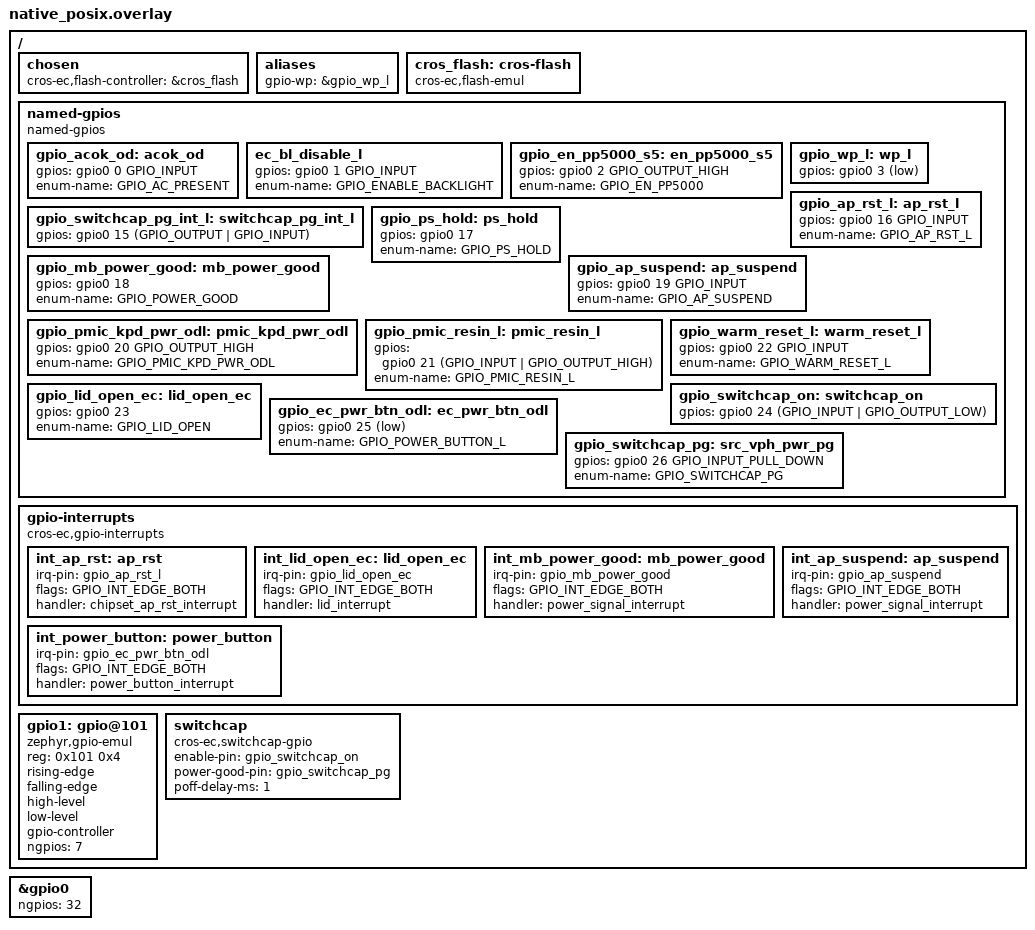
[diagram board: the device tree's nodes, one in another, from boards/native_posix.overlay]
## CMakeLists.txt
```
# Copyright 2021 The ChromiumOS Authors
# Use of this source code is governed by a BSD-style license that can be
# found in the LICENSE file.

cmake_minimum_required(VERSION 3.13.1)
find_package(Zephyr REQUIRED HINTS "${ZEPHYR_BASE}")
project(qcom_power)

# Include the local test directory for shimmed_test_tasks.h
zephyr_include_directories("${CMAKE_CURRENT_SOURCE_DIR}")

FILE(GLOB_RECURSE test_sources src/*.c)
target_sources(app PRIVATE ${test_sources})
```

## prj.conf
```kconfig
# Copyright 2022 The ChromiumOS Authors
# Use of this source code is governed by a BSD-style license that can be
# found in the LICENSE file.

CONFIG_ASSERT=y
CONFIG_PLATFORM_EC_DEBUG_ASSERT=n
CONFIG_TEST=y
CONFIG_ZTEST=y
CONFIG_ZTEST_ASSERT_VERBOSE=1
CONFIG_ZTEST_MOCKING=y

CONFIG_INPUT=y

# Print logs from Zephyr LOG_MODULE to stdout
CONFIG_UART_NATIVE_PTY_0_ON_STDINOUT=y

CONFIG_CROS_EC=y
CONFIG_EMUL=y
CONFIG_FLASH=y
CONFIG_GPIO=y
CONFIG_GPIO_GET_CONFIG=y
CONFIG_PLATFORM_EC=y
CONFIG_RING_BUFFER=y
CONFIG_SERIAL=y
CONFIG_SHELL_BACKEND_DUMMY=y
CONFIG_SHELL_BACKEND_DUMMY_BUF_SIZE=2000
CONFIG_SHELL_BACKEND_SERIAL=n
CONFIG_SHIMMED_TASKS=y

# QCom power sequencing
CONFIG_AP_ARM_QUALCOMM_SC7280=y
CONFIG_PLATFORM_EC_CHIPSET_RESUME_INIT_HOOK=y
CONFIG_PLATFORM_EC_EXTPOWER=y
CONFIG_PLATFORM_EC_EXTPOWER_GPIO=y
CONFIG_PLATFORM_EC_HOSTCMD=y
CONFIG_PLATFORM_EC_LID_SWITCH=y
CONFIG_PLATFORM_EC_POWERSEQ=y
CONFIG_PLATFORM_EC_POWERSEQ_HOST_SLEEP=y
CONFIG_PLATFORM_EC_POWERSEQ_SC7280=y
CONFIG_PLATFORM_EC_POWER_BUTTON=y
CONFIG_PLATFORM_EC_POWER_SLEEP_FAILURE_DETECTION=y
```

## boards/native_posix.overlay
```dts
/* Copyright 2022 The ChromiumOS Authors
 * Use of this source code is governed by a BSD-style license that can be
 * found in the LICENSE file.
 */

#include <board-overlays/native_posix.dts>
#include <dt-bindings/gpio_defines.h>
#include <cros/binman.dtsi>

/ {
	chosen {
		cros-ec,flash-controller = &cros_flash;
	};
	aliases {
		gpio-wp = &gpio_wp_l;
	};
	cros_flash: cros-flash {
		compatible = "cros-ec,flash-emul";
	};

	/*
	 * Keep these GPIOs in pin order.
	 * If you need to add one, make sure you increase
	 * ngpios in the gpio0 node further down.
	 */
	named-gpios {
		compatible = "named-gpios";

		gpio_acok_od: acok_od {
			gpios = <&gpio0 0 GPIO_INPUT>;
			enum-name = "GPIO_AC_PRESENT";
		};
		ec_bl_disable_l {
			gpios = <&gpio0 1 GPIO_INPUT>;
			enum-name = "GPIO_ENABLE_BACKLIGHT";
		};
		gpio_en_pp5000_s5: en_pp5000_s5 {
			gpios = <&gpio0 2 GPIO_OUTPUT_HIGH>;
			enum-name = "GPIO_EN_PP5000";
		};
		gpio_wp_l: wp_l {
			gpios = <&gpio0 3 (GPIO_INPUT | GPIO_ACTIVE_LOW)>;
		};
		gpio_switchcap_pg_int_l: switchcap_pg_int_l {
			gpios = <&gpio0 15 (GPIO_OUTPUT | GPIO_INPUT)>;
		};
		gpio_ap_rst_l: ap_rst_l {
			gpios = <&gpio0 16 GPIO_INPUT>;
			enum-name = "GPIO_AP_RST_L";
		};
		gpio_ps_hold: ps_hold {
			gpios = <&gpio0 17 (GPIO_INPUT | GPIO_PULL_DOWN)>;
			enum-name = "GPIO_PS_HOLD";
		};
		gpio_mb_power_good: mb_power_good {
			gpios = <&gpio0 18 (GPIO_INPUT | GPIO_PULL_DOWN)>;
			enum-name = "GPIO_POWER_GOOD";
		};
		gpio_ap_suspend: ap_suspend {
			gpios = <&gpio0 19 GPIO_INPUT>;
			enum-name = "GPIO_AP_SUSPEND";
		};
		gpio_pmic_kpd_pwr_odl: pmic_kpd_pwr_odl {
			gpios = <&gpio0 20 GPIO_OUTPUT_HIGH>;
			enum-name = "GPIO_PMIC_KPD_PWR_ODL";
		};
		gpio_pmic_resin_l: pmic_resin_l {
			/* Real hardware will allow reading even if GPIO_INPUT
			 * is not set, but the gpio_emul will not.
			 */
			gpios = <&gpio0 21 (GPIO_INPUT | GPIO_OUTPUT_HIGH)>;
			enum-name = "GPIO_PMIC_RESIN_L";
		};
		gpio_warm_reset_l: warm_reset_l {
			gpios = <&gpio0 22 GPIO_INPUT>;
			enum-name = "GPIO_WARM_RESET_L";
		};
		gpio_lid_open_ec: lid_open_ec {
			/* GPIO_PULL_UP will cause this start asserted. */
			gpios = <&gpio0 23 (GPIO_INPUT | GPIO_PULL_UP)>;
			enum-name = "GPIO_LID_OPEN";
		};
		gpio_switchcap_on: switchcap_on {
			gpios = <&gpio0 24 (GPIO_INPUT | GPIO_OUTPUT_LOW)>;
		};
		gpio_ec_pwr_btn_odl: ec_pwr_btn_odl {
			/* GPIO_PULL_UP will cause this start asserted,
			 * i.e. not pressed.
			 */
			gpios = <&gpio0 25 (GPIO_INPUT | GPIO_ACTIVE_LOW | GPIO_PULL_UP)>;
			enum-name = "GPIO_POWER_BUTTON_L";
		};
		gpio_switchcap_pg: src_vph_pwr_pg {
			gpios = <&gpio0 26 GPIO_INPUT_PULL_DOWN>;
			enum-name = "GPIO_SWITCHCAP_PG";
		};
	};

	gpio-interrupts {
		compatible = "cros-ec,gpio-interrupts";

		int_ap_rst: ap_rst {
			irq-pin = <&gpio_ap_rst_l>;
			flags = <GPIO_INT_EDGE_BOTH>;
			handler = "chipset_ap_rst_interrupt";
		};
		int_lid_open_ec: lid_open_ec {
			irq-pin = <&gpio_lid_open_ec>;
			flags = <GPIO_INT_EDGE_BOTH>;
			handler = "lid_interrupt";
		};
		int_mb_power_good: mb_power_good {
			irq-pin = <&gpio_mb_power_good>;
			flags = <GPIO_INT_EDGE_BOTH>;
			handler = "power_signal_interrupt";
		};
		int_ap_suspend: ap_suspend {
			irq-pin = <&gpio_ap_suspend>;
			flags = <GPIO_INT_EDGE_BOTH>;
			handler = "power_signal_interrupt";
		};
		int_power_button: power_button {
			irq-pin = <&gpio_ec_pwr_btn_odl>;
			flags = <GPIO_INT_EDGE_BOTH>;
			handler = "power_button_interrupt";
		};
	};

	gpio1: gpio@101 {
		status = "okay";
		compatible = "zephyr,gpio-emul";
		reg = <0x101 0x4>;
		rising-edge;
		falling-edge;
		high-level;
		low-level;
		gpio-controller;
		#gpio-cells = <2>;
		ngpios = <7>;
	};

	switchcap {
		compatible = "cros-ec,switchcap-gpio";
		enable-pin = <&gpio_switchcap_on>;
		power-good-pin = <&gpio_switchcap_pg>;
		poff-delay-ms = <1>;
	};
};

&gpio0 {
	ngpios = <32>;
};
```

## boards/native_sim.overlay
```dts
/* Copyright 2022 The ChromiumOS Authors
 * Use of this source code is governed by a BSD-style license that can be
 * found in the LICENSE file.
 */

#include <board-overlays/native_sim.dts>
#include <dt-bindings/gpio_defines.h>
#include <cros/binman.dtsi>

/ {
	chosen {
		cros-ec,flash-controller = &cros_flash;
	};
	aliases {
		gpio-wp = &gpio_wp_l;
	};
	cros_flash: cros-flash {
		compatible = "cros-ec,flash-emul";
	};

	/*
	 * Keep these GPIOs in pin order.
	 * If you need to add one, make sure you increase
	 * ngpios in the gpio0 node further down.
	 */
	named-gpios {
		compatible = "named-gpios";

		gpio_acok_od: acok_od {
			gpios = <&gpio0 0 GPIO_INPUT>;
			enum-name = "GPIO_AC_PRESENT";
		};
		ec_bl_disable_l {
			gpios = <&gpio0 1 GPIO_INPUT>;
			enum-name = "GPIO_ENABLE_BACKLIGHT";
		};
		gpio_en_pp5000_s5: en_pp5000_s5 {
			gpios = <&gpio0 2 GPIO_OUTPUT_HIGH>;
			enum-name = "GPIO_EN_PP5000";
		};
		gpio_wp_l: wp_l {
			gpios = <&gpio0 3 (GPIO_INPUT | GPIO_ACTIVE_LOW)>;
		};
		gpio_switchcap_pg_int_l: switchcap_pg_int_l {
			gpios = <&gpio0 15 (GPIO_OUTPUT | GPIO_INPUT)>;
		};
		gpio_ap_rst_l: ap_rst_l {
			gpios = <&gpio0 16 GPIO_INPUT>;
			enum-name = "GPIO_AP_RST_L";
		};
		gpio_ps_hold: ps_hold {
			gpios = <&gpio0 17 (GPIO_INPUT | GPIO_PULL_DOWN)>;
			enum-name = "GPIO_PS_HOLD";
		};
		gpio_mb_power_good: mb_power_good {
			gpios = <&gpio0 18 (GPIO_INPUT | GPIO_PULL_DOWN)>;
			enum-name = "GPIO_POWER_GOOD";
		};
		gpio_ap_suspend: ap_suspend {
			gpios = <&gpio0 19 GPIO_INPUT>;
			enum-name = "GPIO_AP_SUSPEND";
		};
		gpio_pmic_kpd_pwr_odl: pmic_kpd_pwr_odl {
			gpios = <&gpio0 20 GPIO_OUTPUT_HIGH>;
			enum-name = "GPIO_PMIC_KPD_PWR_ODL";
		};
		gpio_pmic_resin_l: pmic_resin_l {
			/* Real hardware will allow reading even if GPIO_INPUT
			 * is not set, but the gpio_emul will not.
			 */
			gpios = <&gpio0 21 (GPIO_INPUT | GPIO_OUTPUT_HIGH)>;
			enum-name = "GPIO_PMIC_RESIN_L";
		};
		gpio_warm_reset_l: warm_reset_l {
			gpios = <&gpio0 22 GPIO_INPUT>;
			enum-name = "GPIO_WARM_RESET_L";
		};
		gpio_lid_open_ec: lid_open_ec {
			/* GPIO_PULL_UP will cause this start asserted. */
			gpios = <&gpio0 23 (GPIO_INPUT | GPIO_PULL_UP)>;
			enum-name = "GPIO_LID_OPEN";
		};
		gpio_switchcap_on: switchcap_on {
			gpios = <&gpio0 24 (GPIO_INPUT | GPIO_OUTPUT_LOW)>;
		};
		gpio_ec_pwr_btn_odl: ec_pwr_btn_odl {
			/* GPIO_PULL_UP will cause this start asserted,
			 * i.e. not pressed.
			 */
			gpios = <&gpio0 25 (GPIO_INPUT | GPIO_ACTIVE_LOW | GPIO_PULL_UP)>;
			enum-name = "GPIO_POWER_BUTTON_L";
		};
		gpio_switchcap_pg: src_vph_pwr_pg {
			gpios = <&gpio0 26 GPIO_INPUT_PULL_DOWN>;
			enum-name = "GPIO_SWITCHCAP_PG";
		};
	};

	gpio-interrupts {
		compatible = "cros-ec,gpio-interrupts";

		int_ap_rst: ap_rst {
			irq-pin = <&gpio_ap_rst_l>;
			flags = <GPIO_INT_EDGE_BOTH>;
			handler = "chipset_ap_rst_interrupt";
		};
		int_lid_open_ec: lid_open_ec {
			irq-pin = <&gpio_lid_open_ec>;
			flags = <GPIO_INT_EDGE_BOTH>;
			handler = "lid_interrupt";
		};
		int_mb_power_good: mb_power_good {
			irq-pin = <&gpio_mb_power_good>;
			flags = <GPIO_INT_EDGE_BOTH>;
			handler = "power_signal_interrupt";
		};
		int_ap_suspend: ap_suspend {
			irq-pin = <&gpio_ap_suspend>;
			flags = <GPIO_INT_EDGE_BOTH>;
			handler = "power_signal_interrupt";
		};
		int_power_button: power_button {
			irq-pin = <&gpio_ec_pwr_btn_odl>;
			flags = <GPIO_INT_EDGE_BOTH>;
			handler = "power_button_interrupt";
		};
	};

	gpio1: gpio@101 {
		status = "okay";
		compatible = "zephyr,gpio-emul";
		reg = <0x101 0x4>;
		rising-edge;
		falling-edge;
		high-level;
		low-level;
		gpio-controller;
		#gpio-cells = <2>;
		ngpios = <7>;
	};

	switchcap {
		compatible = "cros-ec,switchcap-gpio";
		enable-pin = <&gpio_switchcap_on>;
		power-good-pin = <&gpio_switchcap_pg>;
		poff-delay-ms = <1>;
	};
};

&gpio0 {
	ngpios = <32>;
};
```

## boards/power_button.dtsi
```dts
/* Copyright 2023 The ChromiumOS Authors
 * Use of this source code is governed by a BSD-style license that can be
 * found in the LICENSE file.
 */
#include <dt-bindings/buttons.h>
#include <zephyr/dt-bindings/input/input-event-codes.h>

/ {
	gpio-keys {
		compatible = "gpio-keys";
		debounce-interval-ms = <30>;
		power_button: power_button {
			gpios = <&gpio0 25 (GPIO_ACTIVE_LOW | GPIO_PULL_UP)>;
			/* TODO: use an INPUT_KEY code here. */
			zephyr,code = <BUTTON_POWER>;
		};
	};

};

/* interrupt overrides */
/{
	gpio-interrupts {
		/delete-node/ power_button;
	};
};
```

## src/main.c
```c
/* Copyright 2022 The ChromiumOS Authors
 * Use of this source code is governed by a BSD-style license that can be
 * found in the LICENSE file.
 */

#include "console.h"
#include "ec_app_main.h"
#include "gpio.h"
#include "gpio_signal.h"
#include "hooks.h"
#include "host_command.h"
#include "include/power_button.h"
#include "lid_switch.h"
#include "power.h"
#include "power/qcom.h"
#include "task.h"

#include <setjmp.h>

#include <zephyr/device.h>
#include <zephyr/devicetree.h>
#include <zephyr/drivers/gpio.h>
#include <zephyr/drivers/gpio/gpio_emul.h>
#include <zephyr/fff.h>
#include <zephyr/input/input.h>
#include <zephyr/kernel.h>
#include <zephyr/shell/shell_dummy.h>
#include <zephyr/ztest.h>

#include <dt-bindings/buttons.h>

/* For simplicity, enforce that all the gpios are on the same controller. */
#define GPIO_DEVICE \
	DEVICE_DT_GET(DT_GPIO_CTLR(NAMED_GPIOS_GPIO_NODE(ap_rst_l), gpios))
#define ASSERT_SAME_CONTROLLER(x)                                        \
	BUILD_ASSERT(                                                    \
		DT_DEP_ORD(DT_GPIO_CTLR(NAMED_GPIOS_GPIO_NODE(ap_rst_l), \
					gpios)) ==                       \
		DT_DEP_ORD(DT_GPIO_CTLR(NAMED_GPIOS_GPIO_NODE(x), gpios)))

#define AP_RST_L_PIN DT_GPIO_PIN(NAMED_GPIOS_GPIO_NODE(ap_rst_l), gpios)
ASSERT_SAME_CONTROLLER(ap_rst_l);
#define POWER_GOOD_PIN DT_GPIO_PIN(NAMED_GPIOS_GPIO_NODE(mb_power_good), gpios)
ASSERT_SAME_CONTROLLER(mb_power_good);
#define AP_SUSPEND_PIN DT_GPIO_PIN(NAMED_GPIOS_GPIO_NODE(ap_suspend), gpios)
ASSERT_SAME_CONTROLLER(ap_suspend);
#define SWITCHCAP_PG_PIN \
	DT_GPIO_PIN(NAMED_GPIOS_GPIO_NODE(src_vph_pwr_pg), gpios)
ASSERT_SAME_CONTROLLER(src_vph_pwr_pg);
#define PMIC_RESIN_L_PIN DT_GPIO_PIN(NAMED_GPIOS_GPIO_NODE(pmic_resin_l), gpios)
ASSERT_SAME_CONTROLLER(pmic_resin_l);
#define EC_PWR_BTN_ODL_PIN \
	DT_GPIO_PIN(NAMED_GPIOS_GPIO_NODE(ec_pwr_btn_odl), gpios)
ASSERT_SAME_CONTROLLER(ec_pwr_btn_odl);
#define LID_OPEN_EC_PIN DT_GPIO_PIN(NAMED_GPIOS_GPIO_NODE(lid_open_ec), gpios)
ASSERT_SAME_CONTROLLER(lid_open_ec);
#define PMIC_KPD_PWR_ODL_PIN \
	DT_GPIO_PIN(NAMED_GPIOS_GPIO_NODE(pmic_kpd_pwr_odl), gpios)
ASSERT_SAME_CONTROLLER(pmic_kpd_pwr_odl);

static int chipset_reset_count;
static bool set_power_good_on_reset;

static void do_chipset_reset(void)
{
	chipset_reset_count++;
}
DECLARE_HOOK(HOOK_CHIPSET_RESET, do_chipset_reset, HOOK_PRIO_DEFAULT);

static void do_chipset_shutdown(void)
{
	if (set_power_good_on_reset) {
		static const struct device *gpio_dev = GPIO_DEVICE;

		gpio_emul_input_set(gpio_dev, POWER_GOOD_PIN, 1);
	}
}
DECLARE_HOOK(HOOK_CHIPSET_SHUTDOWN, do_chipset_shutdown, HOOK_PRIO_DEFAULT);

DEFINE_FFF_GLOBALS;

FAKE_VALUE_FUNC(int, system_can_boot_ap);
FAKE_VALUE_FUNC(int, battery_wait_for_stable);
int battery_is_present(void)
{
	return 1;
}

/* Tests the chipset_ap_rst_interrupt() handler when in S3.
 *
 * When the system is in S3, and ap_rst_l is pulsed 1-3 times then
 * HOOK_CHIPSET_RESET hooks will run, and interrupts will be disabled for
 * ap_suspend (see power_chipset_handle_host_sleep_event). This may be
 * artificial, since I'm not sure that this scenario can actually ever happen.
 */
static void do_chipset_ap_rst_interrupt_in_s3(int times)
{
	static const struct device *gpio_dev = GPIO_DEVICE;

	/* Preconditions */
	power_signal_enable_interrupt(GPIO_AP_SUSPEND);
	zassert_ok(gpio_emul_input_set(gpio_dev, AP_SUSPEND_PIN, 1));
	power_set_state(POWER_S3);
	task_wake(TASK_ID_CHIPSET);
	k_sleep(K_MSEC(10));
	zassert_equal(power_get_state(), POWER_S3);

	shell_backend_dummy_clear_output(get_ec_shell());
	chipset_reset_count = 0;

	/* Pulse gpio_ap_rst_l `times` */
	for (int i = 0; i < times; ++i) {
		zassert_ok(gpio_emul_input_set(gpio_dev, AP_RST_L_PIN, 0));
		zassert_ok(gpio_emul_input_set(gpio_dev, AP_RST_L_PIN, 1));
	}

	/* Wait for timeout AP_RST_TRANSITION_TIMEOUT. */
	k_sleep(K_MSEC(500));

	/* Verify that gpio_ap_suspend is ignored. */
	zassert_ok(gpio_emul_input_set(gpio_dev, AP_SUSPEND_PIN, 0));
	k_sleep(K_MSEC(10));
	zassert_equal(power_get_state(), POWER_S3);
	/* Verify that HOOK_CHIPSET_RESET was called once. */
	zassert_equal(chipset_reset_count, 1);
}

ZTEST(qcom_power, test_notify_chipset_reset_s3_timeout)
{
	const char *buffer;
	size_t buffer_size;

	do_chipset_ap_rst_interrupt_in_s3(1);
	buffer = shell_backend_dummy_get_output(get_ec_shell(), &buffer_size);
	zassert_true(strstr(buffer, "AP_RST_L transitions not expected: 1") !=
			     NULL,
		     "Invalid console output %s", buffer);
	zassert_true(strstr(buffer, "Chipset reset: exit s3") != NULL,
		     "Invalid console output %s", buffer);
}

ZTEST(qcom_power, test_notify_chipset_reset_s3)
{
	const char *buffer;
	size_t buffer_size;

	do_chipset_ap_rst_interrupt_in_s3(3);
	buffer = shell_backend_dummy_get_output(get_ec_shell(), &buffer_size);
	zassert_false(strstr(buffer, "AP_RST_L transitions not expected") !=
			      NULL,
		      "Invalid console output %s", buffer);
	zassert_true(strstr(buffer, "Chipset reset: exit s3") != NULL,
		     "Invalid console output %s", buffer);
}

/* Tests the chipset_ap_rst_interrupt() handler when in S0.
 *
 * When the system is in S0, and ap_rst_l is pulsed 1-3 times then
 * HOOK_CHIPSET_RESET hooks will run, and that is pretty much all that happens.
 */
static void do_chipset_ap_rst_interrupt_in_s0(int times)
{
	static const struct device *gpio_dev = GPIO_DEVICE;

	shell_backend_dummy_clear_output(get_ec_shell());
	chipset_reset_count = 0;

	/* Pulse gpio_ap_rst_l `times` */
	for (int i = 0; i < times; ++i) {
		zassert_ok(gpio_emul_input_set(gpio_dev, AP_RST_L_PIN, 0));
		zassert_ok(gpio_emul_input_set(gpio_dev, AP_RST_L_PIN, 1));
	}

	/* Wait for timeout AP_RST_TRANSITION_TIMEOUT. */
	k_sleep(K_MSEC(500));

	/* Verify that HOOK_CHIPSET_RESET was called once. */
	zassert_equal(chipset_reset_count, 1);
}

ZTEST(qcom_power, test_notify_chipset_reset_s0_timeout)
{
	const char *buffer;
	size_t buffer_size;

	do_chipset_ap_rst_interrupt_in_s0(1);
	buffer = shell_backend_dummy_get_output(get_ec_shell(), &buffer_size);
	zassert_true(strstr(buffer, "AP_RST_L transitions not expected: 1") !=
			     NULL,
		     "Invalid console output %s", buffer);
	zassert_false(strstr(buffer, "Chipset reset: exit s3") != NULL,
		      "Invalid console output %s", buffer);
}

ZTEST(qcom_power, test_notify_chipset_reset_s0)
{
	const char *buffer;
	size_t buffer_size;

	do_chipset_ap_rst_interrupt_in_s0(3);
	buffer = shell_backend_dummy_get_output(get_ec_shell(), &buffer_size);
	zassert_false(strstr(buffer, "AP_RST_L transitions not expected") !=
			      NULL,
		      "Invalid console output %s", buffer);
	zassert_false(strstr(buffer, "Chipset reset: exit s3") != NULL,
		      "Invalid console output %s", buffer);
}

/* Call chipset_reset, don't provide signals from AP. Verify logs. */
ZTEST(qcom_power, test_chipset_reset_timeout)
{
	const char *buffer;
	size_t buffer_size;

	/* Reset. The reason doesn't really matter. */
	shell_backend_dummy_clear_output(get_ec_shell());
	chipset_reset(CHIPSET_RESET_KB_WARM_REBOOT);
	/* Long enough for the cold reset. */
	k_sleep(K_SECONDS(10));

	/* Verify logged messages. */
	buffer = shell_backend_dummy_get_output(get_ec_shell(), &buffer_size);
	zassert_true(strstr(buffer,
			    "AP refuses to warm reset. Cold resetting") != NULL,
		     "Invalid console output %s", buffer);
	zassert_true(strstr(buffer, "power state 1 = S5") != NULL,
		     "Invalid console output %s", buffer);
	zassert_equal(power_get_state(), POWER_S0);
}

static struct gpio_callback gpio_callback;

/* warm_reset_seq pulses PMIC_RESIN_L, at the end of that pulse set AP_RST_L. */
void warm_reset_callback(const struct device *gpio_dev,
			 struct gpio_callback *callback_struct,
			 gpio_port_pins_t pins)
{
	if ((pins & BIT(PMIC_RESIN_L_PIN)) == 0) {
		return;
	}
	if (gpio_emul_output_get(gpio_dev, PMIC_RESIN_L_PIN)) {
		gpio_emul_input_set(gpio_dev, AP_RST_L_PIN, 0);
	}
}

static void set_power_good(struct k_work *work)
{
	static const struct device *gpio_dev = GPIO_DEVICE;

	gpio_emul_input_set(gpio_dev, POWER_GOOD_PIN, 1);
}
K_WORK_DEFINE(set_power_good_work, set_power_good);

/* PMIC_KPD_PWR_ODL is a signal to turn the power on. The signal that
 * it worked is POWER_GOOD.
 */
void power_good_callback(const struct device *gpio_dev,
			 struct gpio_callback *callback_struct,
			 gpio_port_pins_t pins)
{
	if ((pins & BIT(PMIC_KPD_PWR_ODL_PIN)) == 0) {
		return;
	}
	if (!gpio_emul_output_get(gpio_dev, PMIC_KPD_PWR_ODL_PIN)) {
		/* Set power good in the work queue, instead of now. */
		k_work_submit(&set_power_good_work);
	}
}

/* Call chipset_reset, wait for PMIC_RESIN_L, pulse ap_rsl_l. */
ZTEST(qcom_power, test_chipset_reset_success)
{
	static const struct device *gpio_dev = GPIO_DEVICE;
	const char *buffer;
	size_t buffer_size;

	/* Setup callback. */
	gpio_init_callback(&gpio_callback, warm_reset_callback,
			   BIT(PMIC_RESIN_L_PIN));
	zassert_ok(gpio_add_callback(gpio_dev, &gpio_callback));
	zassert_ok(gpio_pin_interrupt_configure(gpio_dev, PMIC_RESIN_L_PIN,
						GPIO_INT_EDGE_BOTH));

	/* Reset. The reason doesn't really matter. */
	shell_backend_dummy_clear_output(get_ec_shell());
	chipset_reset(CHIPSET_RESET_KB_WARM_REBOOT);
	k_sleep(K_MSEC(100));
	gpio_emul_input_set(gpio_dev, AP_RST_L_PIN, 1);
	/* Long enough for a cold reset, although we don't expect one. */
	k_sleep(K_MSEC(1000));

	/* Verify logged messages. */
	buffer = shell_backend_dummy_get_output(get_ec_shell(), &buffer_size);
	zassert_false(strstr(buffer,
			     "AP refuses to warm reset. Cold resetting") !=
			      NULL,
		      "Invalid console output %s", buffer);
	zassert_false(strstr(buffer, "power state 1 = S5") != NULL,
		      "Invalid console output %s", buffer);
	zassert_equal(power_get_state(), POWER_S0);
}

/* Sent the host command, set the gpio, wait for transition to S3. */
ZTEST(qcom_power, test_request_sleep)
{
	static const struct device *gpio_dev = GPIO_DEVICE;
	struct ec_params_host_sleep_event params = {
		.sleep_event = HOST_SLEEP_EVENT_S3_SUSPEND,
	};

	zassert_ok(ec_cmd_host_sleep_event(NULL, &params));
	zassert_ok(gpio_emul_input_set(gpio_dev, AP_SUSPEND_PIN, 1));
	k_sleep(K_SECONDS(16));
	zassert_equal(power_get_state(), POWER_S3);
	zassert_false(host_is_event_set(EC_HOST_EVENT_HANG_DETECT));
}

/* Sent the host command, don't set the gpio, look for host event. */
ZTEST(qcom_power, test_request_sleep_timeout)
{
	const char *buffer;
	size_t buffer_size;
	struct ec_params_host_sleep_event params = {
		.sleep_event = HOST_SLEEP_EVENT_S3_SUSPEND,
	};

	shell_backend_dummy_clear_output(get_ec_shell());
	zassert_ok(ec_cmd_host_sleep_event(NULL, &params));
	k_sleep(K_SECONDS(16));
	zassert_equal(power_get_state(), POWER_S0);
	buffer = shell_backend_dummy_get_output(get_ec_shell(), &buffer_size);
#if defined(SECTION_IS_RW)
	zassert_true(strstr(buffer, "Detected sleep hang!") != NULL,
		     "Invalid console output %s", buffer);
	zassert_true(host_is_event_set(EC_HOST_EVENT_HANG_DETECT));
#endif /* SECTION_IS_RW */
}

ZTEST(qcom_power, test_chipset_force_shutdown)
{
	chipset_force_shutdown(CHIPSET_SHUTDOWN_G3);
	k_sleep(K_SECONDS(11));
	zassert_equal(power_get_state(), POWER_G3);
}

ZTEST(qcom_power, test_power_button)
{
	static const struct device *gpio_dev = GPIO_DEVICE;

	/* Setup callback. */
	gpio_init_callback(&gpio_callback, power_good_callback,
			   BIT(PMIC_KPD_PWR_ODL_PIN));
	zassert_ok(gpio_add_callback(gpio_dev, &gpio_callback));

	power_set_state(POWER_G3);
	zassert_ok(gpio_emul_input_set(gpio_dev, POWER_GOOD_PIN, 0));
	zassert_ok(gpio_emul_input_set(gpio_dev, PMIC_RESIN_L_PIN, 1));
	k_sleep(K_MSEC(10));
	zassert_equal(power_get_state(), POWER_G3);

	zassert_ok(gpio_emul_input_set(gpio_dev, EC_PWR_BTN_ODL_PIN, 0));
	k_sleep(K_MSEC(100));
	zassert_equal(power_button_signal_asserted(), 1);
	zassert_ok(gpio_emul_input_set(gpio_dev, EC_PWR_BTN_ODL_PIN, 1));
	k_sleep(K_MSEC(500));
	zassert_equal(power_button_signal_asserted(), 0);
	zassert_equal(power_get_state(), POWER_S0);
}

#ifdef CONFIG_INPUT_GPIO_KEYS

ZTEST(qcom_power, test_power_button_input_event)
{
	const struct device *dev = DEVICE_DT_GET_ONE(gpio_keys);

	zassert_equal(power_button_is_pressed(), 0);

	input_report_key(dev, BUTTON_POWER, 1, true, K_FOREVER);
	zassert_equal(power_button_is_pressed(), 1);

	input_report_key(dev, BUTTON_RECOVERY, 1, true, K_FOREVER);
	zassert_equal(power_button_is_pressed(), 1);

	input_report_abs(dev, INPUT_ABS_X, 1, true, K_FOREVER);
	zassert_equal(power_button_is_pressed(), 1);

	input_report_key(dev, BUTTON_POWER, 0, true, K_FOREVER);
	zassert_equal(power_button_is_pressed(), 0);
}

#endif

ZTEST(qcom_power, test_power_button_no_power_good)
{
	static const struct device *gpio_dev = GPIO_DEVICE;

	zassert_ok(gpio_emul_input_set(gpio_dev, POWER_GOOD_PIN, 0));
	power_set_state(POWER_G3);
	k_sleep(K_MSEC(10));
	zassert_equal(power_get_state(), POWER_G3);

	zassert_ok(gpio_emul_input_set(gpio_dev, EC_PWR_BTN_ODL_PIN, 0));
	k_sleep(K_MSEC(100));
	zassert_ok(gpio_emul_input_set(gpio_dev, EC_PWR_BTN_ODL_PIN, 1));
	k_sleep(K_MSEC(1500));
	zassert_equal(power_get_state(), POWER_S5, "power_state=%d",
		      power_get_state());
}

ZTEST(qcom_power, test_power_button_no_switchcap_good)
{
	static const struct device *gpio_dev = GPIO_DEVICE;

	zassert_ok(gpio_emul_input_set(gpio_dev, SWITCHCAP_PG_PIN, 0));
	power_set_state(POWER_G3);
	k_sleep(K_MSEC(10));
	zassert_equal(power_get_state(), POWER_G3);

	zassert_ok(gpio_emul_input_set(gpio_dev, EC_PWR_BTN_ODL_PIN, 0));
	k_sleep(K_MSEC(100));
	zassert_ok(gpio_emul_input_set(gpio_dev, EC_PWR_BTN_ODL_PIN, 1));
	k_sleep(K_SECONDS(10));
	zassert_equal(power_get_state(), POWER_S5, "power_state=%d",
		      power_get_state());
}

ZTEST(qcom_power, test_power_button_no_pmic_resin_pullup)
{
	const char *buffer;
	size_t buffer_size;
	static const struct device *gpio_dev = GPIO_DEVICE;

	power_set_state(POWER_G3);
	k_sleep(K_MSEC(10));
	zassert_equal(power_get_state(), POWER_G3);

	shell_backend_dummy_clear_output(get_ec_shell());
	zassert_ok(gpio_emul_input_set(gpio_dev, POWER_GOOD_PIN, 0));
	zassert_ok(gpio_emul_input_set(gpio_dev, PMIC_RESIN_L_PIN, 0));
	zassert_ok(gpio_emul_input_set(gpio_dev, EC_PWR_BTN_ODL_PIN, 0));
	k_sleep(K_MSEC(100));
	zassert_ok(gpio_emul_input_set(gpio_dev, EC_PWR_BTN_ODL_PIN, 1));
	k_sleep(K_SECONDS(10));
	zassert_equal(power_get_state(), POWER_S5, "power_state=%d",
		      power_get_state());

	buffer = shell_backend_dummy_get_output(get_ec_shell(), &buffer_size);
	zassert_not_null(strstr(buffer, "PMIC_RESIN_L not pulled up by PMIC"),
			 "Invalid console output %s", buffer);
}

ZTEST(qcom_power, test_power_button_battery_low)
{
	static const struct device *gpio_dev = GPIO_DEVICE;

	RESET_FAKE(system_can_boot_ap);
	system_can_boot_ap_fake.return_val = 0;

	power_set_state(POWER_G3);
	k_sleep(K_MSEC(10));
	zassert_equal(power_get_state(), POWER_G3);

	zassert_ok(gpio_emul_input_set(gpio_dev, EC_PWR_BTN_ODL_PIN, 0));
	k_sleep(K_MSEC(100));
	zassert_ok(gpio_emul_input_set(gpio_dev, EC_PWR_BTN_ODL_PIN, 1));
	/* > CAN_BOOT_AP_CHECK_TIMEOUT + CAN_BOOT_AP_CHECK_WAIT */
	k_sleep(K_MSEC(1800));
	zassert_equal(power_get_state(), POWER_S5);
}

ZTEST(qcom_power, test_host_sleep_event_resume)
{
	static const struct device *gpio_dev = GPIO_DEVICE;
	struct ec_params_host_sleep_event params = {
		.sleep_event = HOST_SLEEP_EVENT_S3_RESUME,
	};

	/* Get into S3 first */
	power_signal_enable_interrupt(GPIO_AP_SUSPEND);
	zassert_ok(gpio_emul_input_set(gpio_dev, AP_SUSPEND_PIN, 1));
	power_set_state(POWER_S3);
	task_wake(TASK_ID_CHIPSET);
	k_sleep(K_MSEC(10));
	zassert_equal(power_get_state(), POWER_S3);

	/* Exit suspend via gpio. */
	zassert_ok(gpio_emul_input_set(gpio_dev, AP_SUSPEND_PIN, 0));
	k_sleep(K_MSEC(100));
	zassert_equal(power_get_state(), POWER_S0, "power_state=%d",
		      power_get_state());

	/* Call host command to notify ec resume is done. */
	zassert_ok(ec_cmd_host_sleep_event(NULL, &params));
	k_sleep(K_MSEC(10));
	zassert_equal(power_get_state(), POWER_S0, "power_state=%d",
		      power_get_state());

	/* Check that AP_SUSPEND interrupts are disabled & we are in S0. */
	zassert_ok(gpio_emul_input_set(gpio_dev, AP_SUSPEND_PIN, 1));
	k_sleep(K_MSEC(100));
	zassert_equal(power_get_state(), POWER_S0);
}

ZTEST(qcom_power, test_power_button_off)
{
	static const struct device *gpio_dev = GPIO_DEVICE;

	zassert_ok(gpio_emul_input_set(gpio_dev, EC_PWR_BTN_ODL_PIN, 0));
	k_sleep(K_SECONDS(9));
	zassert_ok(gpio_emul_input_set(gpio_dev, EC_PWR_BTN_ODL_PIN, 1));
	k_sleep(K_MSEC(500));
	zassert_equal(power_get_state(), POWER_S5);
}

ZTEST(qcom_power, test_power_button_off_cancel)
{
	static const struct device *gpio_dev = GPIO_DEVICE;

	zassert_ok(gpio_emul_input_set(gpio_dev, EC_PWR_BTN_ODL_PIN, 0));
	k_sleep(K_SECONDS(4));
	zassert_ok(gpio_emul_input_set(gpio_dev, EC_PWR_BTN_ODL_PIN, 1));
	k_sleep(K_MSEC(500));
	zassert_equal(power_get_state(), POWER_S0);
}

ZTEST(qcom_power, test_no_power_good)
{
	const char *buffer;
	size_t buffer_size;
	static const struct device *gpio_dev = GPIO_DEVICE;

	shell_backend_dummy_clear_output(get_ec_shell());
	zassert_ok(gpio_emul_input_set(gpio_dev, POWER_GOOD_PIN, 0));
	k_sleep(K_MSEC(500));
	zassert_equal(power_get_state(), POWER_S5, "power_state=%d",
		      power_get_state());
	buffer = shell_backend_dummy_get_output(get_ec_shell(), &buffer_size);
	zassert_true(strstr(buffer, "POWER_GOOD is lost") != NULL,
		     "Invalid console output %s", buffer);
}

ZTEST(qcom_power, test_no_power_good_then_good)
{
	const char *buffer;
	size_t buffer_size;
	static const struct device *gpio_dev = GPIO_DEVICE;

	shell_backend_dummy_clear_output(get_ec_shell());
	zassert_ok(gpio_emul_input_set(gpio_dev, POWER_GOOD_PIN, 0));
	set_power_good_on_reset = true;
	k_sleep(K_MSEC(500));
	zassert_equal(power_get_state(), POWER_S5, "power_state=%d",
		      power_get_state());
	buffer = shell_backend_dummy_get_output(get_ec_shell(), &buffer_size);
	zassert_true(strstr(buffer, "POWER_GOOD is lost") != NULL,
		     "Invalid console output %s", buffer);
	zassert_true(strstr(buffer, "POWER_GOOD up again after lost") != NULL,
		     "Invalid console output %s", buffer);
}

ZTEST(qcom_power, test_lid_open_power_on)
{
	static const struct device *gpio_dev = GPIO_DEVICE;

	zassert_ok(gpio_emul_input_set(gpio_dev, LID_OPEN_EC_PIN, 0));
	power_set_state(POWER_G3);
	k_sleep(K_MSEC(100));
	zassert_equal(power_get_state(), POWER_G3);
	zassert_false(lid_is_open());

	zassert_ok(gpio_emul_input_set(gpio_dev, LID_OPEN_EC_PIN, 1));
	k_sleep(K_MSEC(500));
	zassert_equal(power_get_state(), POWER_S0, "power_state=%d",
		      power_get_state());
}

/* chipset_power_on is called by USB code on dock power button release. */
ZTEST(qcom_power, test_chipset_power_on)
{
	power_set_state(POWER_G3);
	k_sleep(K_MSEC(100));
	zassert_equal(power_get_state(), POWER_G3);

	chipset_power_on();
	k_sleep(K_MSEC(500));
	zassert_equal(power_get_state(), POWER_S0, "power_state=%d",
		      power_get_state());
}

static jmp_buf assert_jumpdata;
static int num_asserts;

void assert_post_action(const char *file, unsigned int line)
{
	++num_asserts;
	longjmp(assert_jumpdata, 1);
}

ZTEST(qcom_power, test_invalid_power_state)
{
	if (setjmp(assert_jumpdata) == 0) {
		power_handle_state(POWER_S4);
		zassert_unreachable();
	}
	zassert_equal(num_asserts, 1);
}

ZTEST(qcom_power, test_power_chipset_init_sysjump_power_good)
{
	system_set_reset_flags(EC_RESET_FLAG_SYSJUMP);
	zassert_equal(power_chipset_init(), POWER_S0);
	power_set_state(POWER_S0);

	task_wake(TASK_ID_CHIPSET);
	k_sleep(K_MSEC(500));
	zassert_equal(power_get_state(), POWER_S0, "power_state=%d",
		      power_get_state());
	zassert_equal(power_has_signals(POWER_SIGNAL_MASK(0)), 0);
}

ZTEST(qcom_power, test_power_chipset_init_sysjump_power_off)
{
	static const struct device *gpio_dev = GPIO_DEVICE;

	zassert_ok(gpio_emul_input_set(gpio_dev, POWER_GOOD_PIN, 0));
	system_set_reset_flags(EC_RESET_FLAG_SYSJUMP);
	zassert_equal(power_chipset_init(), POWER_G3);
	power_set_state(POWER_G3);

	task_wake(TASK_ID_CHIPSET);
	k_sleep(K_MSEC(500));
	zassert_equal(power_get_state(), POWER_G3, "power_state=%d",
		      power_get_state());
}

ZTEST(qcom_power, test_power_chipset_init_ap_off)
{
	system_set_reset_flags(EC_RESET_FLAG_AP_OFF);
	zassert_equal(power_chipset_init(), POWER_G3);
	power_set_state(POWER_G3);

	task_wake(TASK_ID_CHIPSET);
	k_sleep(K_MSEC(500));
	zassert_equal(power_get_state(), POWER_G3, "power_state=%d",
		      power_get_state());
}

void start_in_s0(void *fixture)
{
	static const struct device *gpio_dev = GPIO_DEVICE;

	RESET_FAKE(system_can_boot_ap);
	system_can_boot_ap_fake.return_val = 1;
	set_power_good_on_reset = false;

	power_signal_disable_interrupt(GPIO_AP_SUSPEND);
	power_signal_enable_interrupt(GPIO_AP_RST_L);
	zassert_ok(gpio_emul_input_set(gpio_dev, POWER_GOOD_PIN, 1));
	zassert_ok(gpio_emul_input_set(gpio_dev, AP_SUSPEND_PIN, 0));
	zassert_ok(gpio_emul_input_set(gpio_dev, AP_RST_L_PIN, 1));
	zassert_ok(gpio_emul_input_set(gpio_dev, SWITCHCAP_PG_PIN, 1));
	zassert_ok(gpio_pin_set(gpio_dev, PMIC_RESIN_L_PIN, 1));
	zassert_ok(gpio_emul_input_set(gpio_dev, LID_OPEN_EC_PIN, 1));
	power_set_state(POWER_S0);
	power_signal_interrupt(GPIO_AP_SUSPEND);
	task_wake(TASK_ID_CHIPSET);
	/* Wait for timeout AP_RST_TRANSITION_TIMEOUT. */
	k_sleep(K_MSEC(500));
	zassert_equal(power_get_state(), POWER_S0, "power_state=%d",
		      power_get_state());
	zassert_equal(power_has_signals(POWER_SIGNAL_MASK(0)), 0);
}

void qcom_cleanup(void *fixture)
{
	if (gpio_callback.handler != NULL) {
		static const struct device *gpio_dev = GPIO_DEVICE;

		gpio_remove_callback(gpio_dev, &gpio_callback);
		gpio_callback.handler = NULL;
	}
	host_clear_events(EC_HOST_EVENT_MASK(EC_HOST_EVENT_HANG_DETECT));
	system_clear_reset_flags(EC_RESET_FLAG_SYSJUMP | EC_RESET_FLAG_AP_OFF);
}

ZTEST_SUITE(qcom_power, NULL, NULL, start_in_s0, qcom_cleanup, NULL);

void test_main(void)
{
	ec_app_main();
	/* Fake sleep long enough to go to S5 and back to G3 again. */
	k_sleep(K_SECONDS(11));

	ztest_run_test_suites(NULL, false, 1, 1);

	ztest_verify_all_test_suites_ran();
}
```
